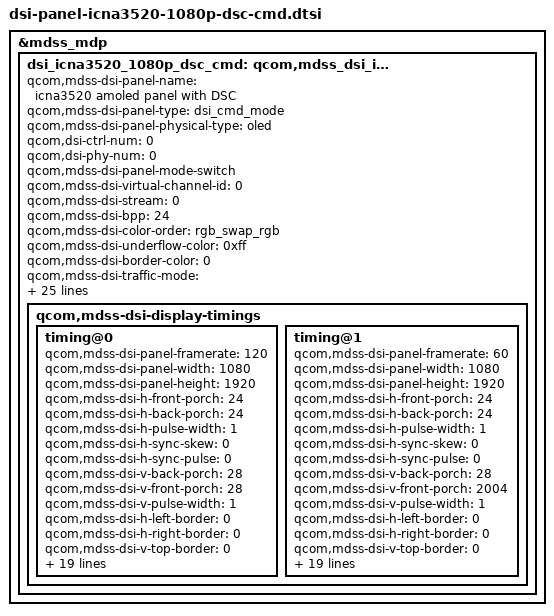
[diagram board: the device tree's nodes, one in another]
/* Copyright (c) 2016-2018, The Linux Foundation. All rights reserved.
 *
 * This program is free software; you can redistribute it and/or modify
 * it under the terms of the GNU General Public License version 2 and
 * only version 2 as published by the Free Software Foundation.
 *
 * This program is distributed in the hope that it will be useful,
 * but WITHOUT ANY WARRANTY; without even the implied warranty of
 * MERCHANTABILITY or FITNESS FOR A PARTICULAR PURPOSE.  See the
 * GNU General Public License for more details.
 */

&mdss_mdp {
	dsi_icna3520_1080p_dsc_cmd: qcom,mdss_dsi_icna3520_dsc_cmd {
		qcom,mdss-dsi-panel-name = "icna3520 amoled panel with DSC";
		qcom,mdss-dsi-panel-type = "dsi_cmd_mode";
		qcom,mdss-dsi-panel-physical-type = "oled";
		qcom,dsi-ctrl-num = <0>;
		qcom,dsi-phy-num = <0>;

		qcom,mdss-dsi-panel-mode-switch;

		qcom,mdss-dsi-virtual-channel-id = <0>;
		qcom,mdss-dsi-stream = <0>;
		qcom,mdss-dsi-bpp = <24>;
		qcom,mdss-dsi-color-order = "rgb_swap_rgb";
		qcom,mdss-dsi-underflow-color = <0xff>;
		qcom,mdss-dsi-border-color = <0>;

		qcom,mdss-dsi-traffic-mode = "non_burst_sync_event";
		qcom,mdss-dsi-lane-map = "lane_map_0123";
		qcom,mdss-dsi-bllp-eof-power-mode;
		qcom,mdss-dsi-bllp-power-mode;
		qcom,mdss-dsi-lane-0-state;
		qcom,mdss-dsi-lane-1-state;
		qcom,mdss-dsi-lane-2-state;
		qcom,mdss-dsi-lane-3-state;
		qcom,mdss-dsi-dma-trigger = "trigger_sw";
		qcom,mdss-dsi-mdp-trigger = "none";
		qcom,mdss-dsi-reset-sequence = <1 20>, <0 20>, <1 20>;
		qcom,mdss-dsi-te-pin-select = <1>;
		qcom,mdss-dsi-wr-mem-start = <0x2c>;
		qcom,mdss-dsi-wr-mem-continue = <0x3c>;
		qcom,mdss-dsi-te-dcs-command = <1>;
		qcom,mdss-dsi-te-check-enable;
		qcom,mdss-dsi-te-using-te-pin;
		qcom,mdss-dsi-force-clock-lane-hs;
		qcom,mdss-dsi-panel-hdr-enabled;
		qcom,mdss-dsi-panel-hdr-color-primaries = <14500 15500 32000
			17000 15500 30000 8000 3000>;
		qcom,mdss-dsi-panel-peak-brightness = <4200000>;
		qcom,mdss-dsi-panel-blackness-level = <3230>;
		qcom,quec-refresh-120hz = <0x1c>;
		qcom,quec-refresh-60hz = <0x7d6>;

		qcom,mdss-dsi-display-timings {
			timing@0 {
				qcom,mdss-dsi-panel-framerate = <120>;
				qcom,mdss-dsi-panel-width = <1080>;
				qcom,mdss-dsi-panel-height = <1920>;
				qcom,mdss-dsi-h-front-porch = <24>;
				qcom,mdss-dsi-h-back-porch = <24>;
				qcom,mdss-dsi-h-pulse-width = <1>;
				qcom,mdss-dsi-h-sync-skew = <0>;
				qcom,mdss-dsi-h-sync-pulse = <0>;
				qcom,mdss-dsi-v-back-porch = <28>;
				qcom,mdss-dsi-v-front-porch = <28>;
				qcom,mdss-dsi-v-pulse-width = <1>;
				qcom,mdss-dsi-h-left-border = <0>;
				qcom,mdss-dsi-h-right-border = <0>;
				qcom,mdss-dsi-v-top-border = <0>;
				qcom,mdss-dsi-v-bottom-border = <0>;
				qcom,mdss-dsi-panel-jitter = <0x3 0x1>;

				qcom,mdss-dsi-timing-switch-command = <0x39010000 0x248 0x390100 0x2 0x9f003901 0x0 0x7b300d8 0x1c001c>;
				qcom,mdss-dsi-timing-switch-command-state = "dsi_lp_mode";

				qcom,mdss-dsi-on-command = [39 01 00 00 00 00 03 9c a5 a5 39 01 00 00 00 00 03 fd 5a 5a 39 01 00 00 00 00 02 48 00 39 01 00 00 00 00 02 53 e0 05 01 00 00 00 00 02 35 00 05 01 00 00 78 00 02 11 00 39 01 00 00 00 00 02 9f 00 39 01 00 00 00 00 07 b3 00 d8 00 1c 00 1c 39 01 00 00 00 00 03 51 0d 75 39 01 00 00 00 00 02 9f 01 39 01 00 00 00 00 03 c0 1a 71 39 01 00 00 00 00 21 c1 11 00 00 89 30 80 07 80 04 38 00 0c 02 1c 02 1c 02 00 02 0e 00 20 01 1f 00 07 00 0c 08 bb 08 7a 39 01 00 00 00 00 21 c2 18 00 10 f0 03 0c 20 00 06 0b 0b 33 0e 1c 2a 38 46 54 62 69 70 77 79 7b 7d 7e 01 02 01 00 09 40 39 01 00 00 00 00 19 c3 09 be 19 fc 19 fa 19 f8 1a 38 1a 78 1a b6 2a f6 2b 34 2b 74 3b 74 6b f4 39 01 00 00 00 00 02 9f 0d 39 01 00 00 78 00 02 b2 24 39 01 00 00 00 00 02 9f 01 39 01 00 00 00 00 02 b2 00 05 01 00 00 78 00 02 29 00];
				qcom,mdss-dsi-on-command-state = "dsi_lp_mode";

				qcom,mdss-dsi-off-command = [
					05 01 00 00 14 00 02 28 00 // Display Off
					05 01 00 00 78 00 02 10 00 // Sleep In
				];
				qcom,mdss-dsi-off-command-state = "dsi_hs_mode";

				qcom,compression-mode = "dsc";
				qcom,mdss-dsc-slice-height = <12>;
				qcom,mdss-dsc-slice-width = <540>;
				qcom,mdss-dsc-slice-per-pkt = <2>;
				qcom,mdss-dsc-bit-per-component = <8>;
				qcom,mdss-dsc-bit-per-pixel = <8>;
				qcom,mdss-dsc-block-prediction-enable;
			};

			timing@1 {
				qcom,mdss-dsi-panel-framerate = <60>;
				qcom,mdss-dsi-panel-width = <1080>;
				qcom,mdss-dsi-panel-height = <1920>;
				qcom,mdss-dsi-h-front-porch = <24>;
				qcom,mdss-dsi-h-back-porch = <24>;
				qcom,mdss-dsi-h-pulse-width = <1>;
				qcom,mdss-dsi-h-sync-skew = <0>;
				qcom,mdss-dsi-h-sync-pulse = <0>;
				qcom,mdss-dsi-v-back-porch = <28>;
				qcom,mdss-dsi-v-front-porch = <2004>;
				qcom,mdss-dsi-v-pulse-width = <1>;
				qcom,mdss-dsi-h-left-border = <0>;
				qcom,mdss-dsi-h-right-border = <0>;
				qcom,mdss-dsi-v-top-border = <0>;
				qcom,mdss-dsi-v-bottom-border = <0>;
				qcom,mdss-dsi-panel-jitter = <0x3 0x1>;

				qcom,mdss-dsi-timing-switch-command = <0x39010000 0x248 0x10390100 0x2 0x9f003901 0x0 0xfb300db 0x1c001c 0xdb00 0x1c07d600>;
				qcom,mdss-dsi-timing-switch-command-state = "dsi_lp_mode";

				qcom,mdss-dsi-on-command = [39 01 00 00 00 00 03 9c a5 a5 39 01 00 00 00 00 03 fd 5a 5a 39 01 00 00 00 00 02 48 10 39 01 00 00 00 00 02 53 e0 05 01 00 00 00 00 02 35 00 05 01 00 00 78 00 02 11 00 39 01 00 00 00 00 02 9f 00 39 01 00 00 00 00 0f b3 00 db 00 1c 00 1c 00 00 db 00 1c 07 d6 00 39 01 00 00 00 00 03 51 0d 75 39 01 00 00 00 00 02 9f 01 39 01 00 00 00 00 03 c0 1a 71 39 01 00 00 00 00 21 c1 11 00 00 89 30 80 07 80 04 38 00 0c 02 1c 02 1c 02 00 02 0e 00 20 01 1f 00 07 00 0c 08 bb 08 7a 39 01 00 00 00 00 21 c2 18 00 10 f0 03 0c 20 00 06 0b 0b 33 0e 1c 2a 38 46 54 62 69 70 77 79 7b 7d 7e 01 02 01 00 09 40 39 01 00 00 00 00 19 c3 09 be 19 fc 19 fa 19 f8 1a 38 1a 78 1a b6 2a f6 2b 34 2b 74 3b 74 6b f4 39 01 00 00 00 00 02 9f 0d 39 01 00 00 78 00 02 b2 24 39 01 00 00 00 00 02 9f 01 39 01 00 00 00 00 02 b2 00 05 01 00 00 78 00 02 29 00];
				qcom,mdss-dsi-on-command-state = "dsi_lp_mode";

				qcom,mdss-dsi-off-command = [
					05 01 00 00 14 00 02 28 00 // Display Off
					05 01 00 00 78 00 02 10 00 // Sleep In
				];
				qcom,mdss-dsi-off-command-state = "dsi_hs_mode";

				qcom,compression-mode = "dsc";
				qcom,mdss-dsc-slice-height = <12>;
				qcom,mdss-dsc-slice-width = <540>;
				qcom,mdss-dsc-slice-per-pkt = <2>;
				qcom,mdss-dsc-bit-per-component = <8>;
				qcom,mdss-dsc-bit-per-pixel = <8>;
				qcom,mdss-dsc-block-prediction-enable;
			};
		};
	};
};
